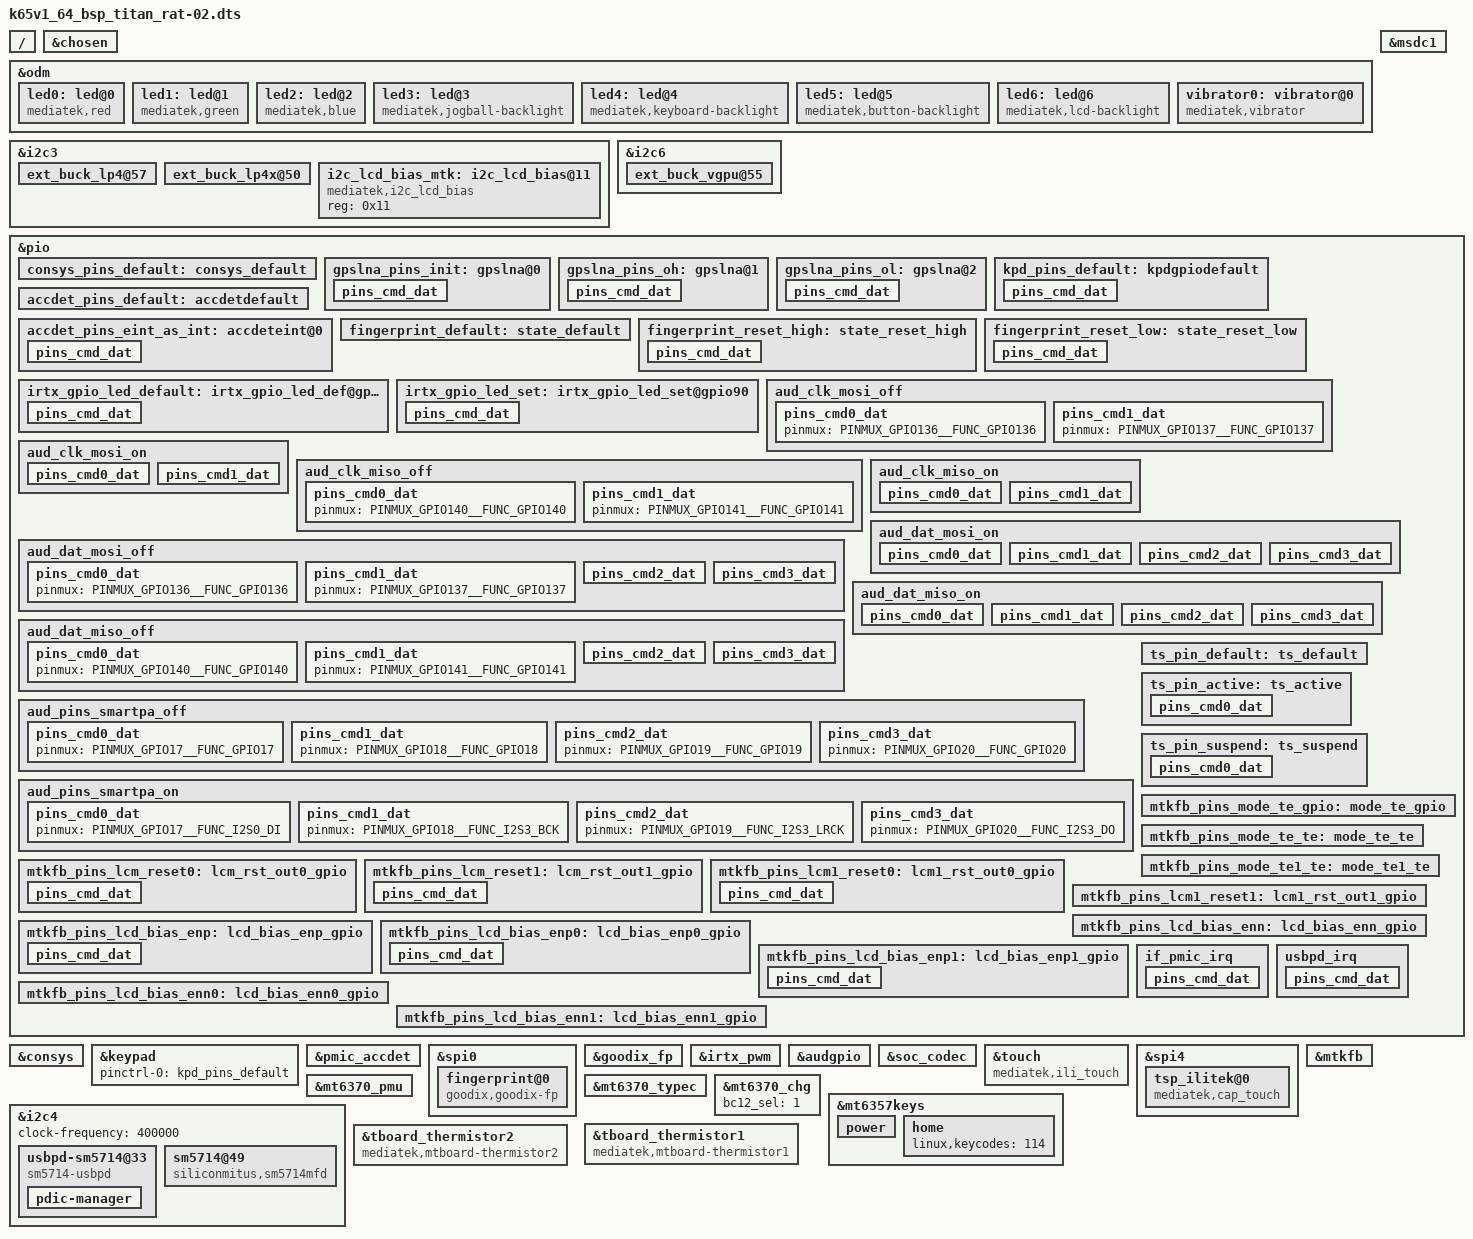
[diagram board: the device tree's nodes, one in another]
// SPDX-License-Identifier: GPL-2.0+
/*
 * Copyright (c) 2019 MediaTek Inc.
 *
 */

#include <dt-bindings/interrupt-controller/arm-gic.h>
#include <dt-bindings/interrupt-controller/irq.h>
#include <dt-bindings/pinctrl/mt6765-pinfunc.h>
#include <dt-bindings/clock/mt6765-clk.h>
#include <dt-bindings/mmc/mt6765-msdc.h>

/dts-v1/;
/plugin/;

/ {
	fragment@model {
	target-path = "/";
		__overlay__ {
			dtbo-hw_rev = <2>;
			dtbo-hw_rev_end = <255>;
		};
	};
};

/* chosen */
&chosen {

	/* fpga may has no lk, we need to specify display info here */
	/* fb buffer is reserved using this dts by memory node above */
	atag,videolfb-fb_base_h = <0x0>;
	atag,videolfb-fb_base_l = <0x5e605000>;
	atag,videolfb-islcmfound = <1>;
	/* because no lk, so lcm is not inited */
	atag,videolfb-islcm_inited = <0>;
	atag,videolfb-fps= <6000>;
	atag,videolfb-vramSize= <0x017bb000>;
	atag,videolfb-lcmname= "nt35695B_fhd_dsi_cmd_auo_rt5081_drv";
};

&odm {
	led0:led@0 {
		compatible = "mediatek,red";
		led_mode = <0>;
		data = <1>;
		pwm_config = <0 0 0 0 0>;
	};
	led1:led@1 {
		compatible = "mediatek,green";
		led_mode = <0>;
		data = <1>;
		pwm_config = <0 0 0 0 0>;
	};
	led2:led@2 {
		compatible = "mediatek,blue";
		led_mode = <0>;
		data = <1>;
		pwm_config = <0 0 0 0 0>;
	};
	led3:led@3 {
		compatible = "mediatek,jogball-backlight";
		led_mode = <0>;
		data = <1>;
		pwm_config = <0 0 0 0 0>;
	};
	led4:led@4 {
		compatible = "mediatek,keyboard-backlight";
		led_mode = <0>;
		data = <1>;
		pwm_config = <0 0 0 0 0>;
	};
	led5:led@5 {
		compatible = "mediatek,button-backlight";
		led_mode = <0>;
		data = <1>;
		pwm_config = <0 0 0 0 0>;
	};
	led6:led@6 {
		compatible = "mediatek,lcd-backlight";
		led_mode = <4>;
		data = <1>;
		pwm_config = <0 3 0 0 0>;
	};
	vibrator0:vibrator@0 {
		compatible = "mediatek,vibrator";
		vib_timer = <25>;
		vib_limit = <9>;
		vib_vol= <9>;
	};
};

/* MSDC1 */
&msdc1 {
	cd_level = /bits/ 8 <MSDC_CD_HIGH>;
	cd-gpios = <&pio 9 0>;
};
/* MSDC1 */

&i2c3 {
	ext_buck_lp4@57 {
		regulator-name ="ext_buck_vdd2";
		regulator-min-microvolt = <300000>;
		regulator-max-microvolt = <1300000>;
		vsel_pin = <0>;
	};

	ext_buck_lp4x@50 {
		regulator-name ="ext_buck_vddq";
		regulator-min-microvolt = <300000>;
		regulator-max-microvolt = <1300000>;
		vsel_pin = <1>;
	};
};

&i2c6 {
	ext_buck_vgpu@55 {
		regulator-name ="ext_buck_vgpu";
		regulator-min-microvolt = <300000>;
		regulator-max-microvolt = <1300000>;
		vsel_pin = <2>;
	};
};

/* CONSYS GPIO standardization */
&pio {
	consys_pins_default: consys_default {
	};
	gpslna_pins_init: gpslna@0 {
		pins_cmd_dat {
			pinmux = <PINMUX_GPIO150__FUNC_GPIO150>;
			output-low;
		};
	};
	gpslna_pins_oh: gpslna@1 {
		pins_cmd_dat {
			pinmux = <PINMUX_GPIO150__FUNC_GPIO150>;
			output-high;
		};
	};
	gpslna_pins_ol: gpslna@2 {
		pins_cmd_dat {
			pinmux = <PINMUX_GPIO150__FUNC_GPIO150>;
			slew-rate = <1>;
			output-low;
		};
	};
};
&consys {
	pinctrl-names = "default", "gps_lna_state_init",
		"gps_lna_state_oh", "gps_lna_state_ol";
	pinctrl-0 = <&consys_pins_default>;
	pinctrl-1 = <&gpslna_pins_init>;
	pinctrl-2 = <&gpslna_pins_oh>;
	pinctrl-3 = <&gpslna_pins_ol>;
	status = "okay";
};
/* CONSYS end */

&keypad {
	pinctrl-names = "default";
	pinctrl-0 = <&kpd_pins_default>;
};

&pio {
	kpd_pins_default: kpdgpiodefault {
		pins_cmd_dat {
			pinmux = <PINMUX_GPIO93__FUNC_KPCOL0>;
			bias-pull-up = <MTK_PUPD_SET_R1R0_10>;
			output-low;
			input-schmitt-enable;
		};
	};
};


/* accdet start */
&pmic_accdet {
	accdet-mic-vol = <6>;
	accdet-plugout-debounce = <1>;
	accdet-mic-mode = <1>;
	headset-mode-setting = <0x500 0x500 1 0x1f0
				0x800 0x800 0x20 0x44>;
	headset-eint-level-pol = <8>;
	headset-use-ap-eint = <0>;
	headset-eint-num = <0>;
	headset-eint-trig-mode = <0>;
	headset-key-mode = <1>;
	/*min_3pole--max_3pole--min_4pole--max_4pole--vol_bias*/
	headset-vol-threshold = <0 590 591 1680 2600>;
	headset-three-key-threshold = <0 80 220 400>;
	headset-three-key-threshold-CDD = <0 121 192 600>;
	headset-four-key-threshold = <0 58 121 192 400>;

	/* moisture SW mode config start, use external resister or not.
	 */
	moisture-ver = <1>;
	moisture_use_ext_res = <1>;
	/* moisture of water resister ohm, SW mode by auxadc*/
	moisture-water-r = <50000>;
	/* moisture SW mode config end */

	pinctrl-names = "default", "state_eint_as_int";
	pinctrl-0 = <&accdet_pins_default>;
	pinctrl-1 = <&accdet_pins_eint_as_int>;
	status = "okay";
};
&pio {
	accdet_pins_default: accdetdefault {
	};
	accdet_pins_eint_as_int: accdeteint@0 {
		pins_cmd_dat {
			pinmux = <PINMUX_GPIO9__FUNC_GPIO9>;
			slew-rate = <0>;
			bias-disable;
		};
	};
};
/* accdet end */

/* FINGERPRINT start */
&spi0 {
	#address-cells = <1>;
	#size-cells = <0>;
	fingerprint@0 {
		compatible = "goodix,goodix-fp";
		reg = <0>;
		spi-max-frequency = <8000000>;
		netlink-event = <30>;
		status = "okay";
	};
};

&goodix_fp {
	pinctrl-names = "default", "reset_high", "reset_low";
	pinctrl-0 = <&fingerprint_default>;
	pinctrl-1 = <&fingerprint_reset_high>;
	pinctrl-2 = <&fingerprint_reset_low>;
	status = "okay";
};

&pio {
	fingerprint_default: state_default {
	};
	fingerprint_reset_high: state_reset_high {
		pins_cmd_dat {
			pinmux = <PINMUX_GPIO172__FUNC_GPIO172>;
			slew-rate = <1>;
			output-high;
		};
	};
	fingerprint_reset_low: state_reset_low {
		pins_cmd_dat {
			pinmux = <PINMUX_GPIO172__FUNC_GPIO172>;
			slew-rate = <1>;
			output-low;
		};
	};
};
/* FINGERPRINT end */

/* IRTX GPIO end */
&irtx_pwm {
	pinctrl-names = "irtx_gpio_led_default", "irtx_gpio_led_set";
	pinctrl-0 = <&irtx_gpio_led_default>;
	pinctrl-1 = <&irtx_gpio_led_set>;
	status = "okay";
};
&pio {
	irtx_gpio_led_default:irtx_gpio_led_def@gpio90 {
		pins_cmd_dat {
			pinmux = <PINMUX_GPIO90__FUNC_GPIO90>;
			slew-rate = <1>;
			bias-disable;
			output-low;
			input-schmitt-enable = <0>;
		};
	};

	irtx_gpio_led_set:irtx_gpio_led_set@gpio90 {
		pins_cmd_dat {
			pinmux = <PINMUX_GPIO90__FUNC_PWM0>;
			slew-rate = <1>;
			output-high;
		};
	};
};
/* IRTX GPIO Settings -End */

/* AUDIO GPIO standardization */
&audgpio {
	pinctrl-names = "aud_clk_mosi_off",
			"aud_clk_mosi_on",
			"aud_clk_miso_off",
			"aud_clk_miso_on",
			"aud_dat_mosi_off",
			"aud_dat_mosi_on",
			"aud_dat_miso_off",
			"aud_dat_miso_on",
			"aud_smartpa_off",
			"aud_smartpa_on";
	pinctrl-0 = <&aud_clk_mosi_off>;
	pinctrl-1 = <&aud_clk_mosi_on>;
	pinctrl-2 = <&aud_clk_miso_off>;
	pinctrl-3 = <&aud_clk_miso_on>;
	pinctrl-4 = <&aud_dat_mosi_off>;
	pinctrl-5 = <&aud_dat_mosi_on>;
	pinctrl-6 = <&aud_dat_miso_off>;
	pinctrl-7 = <&aud_dat_miso_on>;
	pinctrl-8 = <&aud_pins_smartpa_off>;
	pinctrl-9 = <&aud_pins_smartpa_on>;
	status = "okay";
};

&pio {
	aud_clk_mosi_off: aud_clk_mosi_off {
		pins_cmd0_dat {
			pinmux = <PINMUX_GPIO136__FUNC_GPIO136>;
		};
		pins_cmd1_dat {
			pinmux = <PINMUX_GPIO137__FUNC_GPIO137>;
		};
	};

	aud_clk_mosi_on: aud_clk_mosi_on {
		pins_cmd0_dat {
			pinmux = <PINMUX_GPIO136__FUNC_AUD_CLK_MOSI>;
			input-schmitt-enable;
		};
		pins_cmd1_dat {
			pinmux = <PINMUX_GPIO137__FUNC_AUD_SYNC_MOSI>;
			input-schmitt-enable;
		};
	};

	aud_clk_miso_off: aud_clk_miso_off {
		pins_cmd0_dat {
			pinmux = <PINMUX_GPIO140__FUNC_GPIO140>;
		};
		pins_cmd1_dat {
			pinmux = <PINMUX_GPIO141__FUNC_GPIO141>;
		};
	};

	aud_clk_miso_on: aud_clk_miso_on {
		pins_cmd0_dat {
			pinmux = <PINMUX_GPIO140__FUNC_AUD_CLK_MISO>;
			input-schmitt-enable;
		};
		pins_cmd1_dat {
			pinmux = <PINMUX_GPIO141__FUNC_AUD_SYNC_MISO>;
			input-schmitt-enable;
		};
	};

	aud_dat_mosi_off: aud_dat_mosi_off {
		pins_cmd0_dat {
			pinmux = <PINMUX_GPIO136__FUNC_GPIO136>;
		};
		pins_cmd1_dat {
			pinmux = <PINMUX_GPIO137__FUNC_GPIO137>;
		};
		pins_cmd2_dat {
			pinmux = <PINMUX_GPIO138__FUNC_GPIO138>;
			input-enable;
			slew-rate = <0>;
			bias-disable;
		};
		pins_cmd3_dat {
			pinmux = <PINMUX_GPIO139__FUNC_GPIO139>;
			input-enable;
			slew-rate = <0>;
			bias-disable;
		};
	};

	aud_dat_mosi_on: aud_dat_mosi_on {
		pins_cmd0_dat {
			pinmux = <PINMUX_GPIO136__FUNC_AUD_CLK_MOSI>;
			input-schmitt-enable;
		};
		pins_cmd1_dat {
			pinmux = <PINMUX_GPIO137__FUNC_AUD_SYNC_MOSI>;
			input-schmitt-enable;
		};
		pins_cmd2_dat {
			pinmux = <PINMUX_GPIO138__FUNC_AUD_DAT_MOSI0>;
			input-schmitt-enable;
		};
		pins_cmd3_dat {
			pinmux = <PINMUX_GPIO139__FUNC_AUD_DAT_MOSI1>;
			input-schmitt-enable;
		};
	};

	aud_dat_miso_off: aud_dat_miso_off {
		pins_cmd0_dat {
			pinmux = <PINMUX_GPIO140__FUNC_GPIO140>;
		};
		pins_cmd1_dat {
			pinmux = <PINMUX_GPIO141__FUNC_GPIO141>;
		};
		pins_cmd2_dat {
			pinmux = <PINMUX_GPIO142__FUNC_GPIO142>;
			input-enable;
			slew-rate = <0>;
			bias-disable;
		};
		pins_cmd3_dat {
			pinmux = <PINMUX_GPIO143__FUNC_GPIO143>;
			input-enable;
			slew-rate = <0>;
			bias-disable;
		};
	};

	aud_dat_miso_on: aud_dat_miso_on {
		pins_cmd0_dat {
			pinmux = <PINMUX_GPIO140__FUNC_AUD_CLK_MISO>;
			input-schmitt-enable;
		};
		pins_cmd1_dat {
			pinmux = <PINMUX_GPIO141__FUNC_AUD_SYNC_MISO>;
			input-schmitt-enable;
		};
		pins_cmd2_dat {
			pinmux = <PINMUX_GPIO142__FUNC_AUD_DAT_MISO0>;
			input-schmitt-enable;
		};
		pins_cmd3_dat {
			pinmux = <PINMUX_GPIO143__FUNC_AUD_DAT_MISO1>;
			input-schmitt-enable;
		};
	};

	aud_pins_smartpa_off: aud_pins_smartpa_off {
		pins_cmd0_dat {
			pinmux = <PINMUX_GPIO17__FUNC_GPIO17>;
		};
		pins_cmd1_dat {
			pinmux = <PINMUX_GPIO18__FUNC_GPIO18>;
		};
		pins_cmd2_dat {
			pinmux = <PINMUX_GPIO19__FUNC_GPIO19>;
		};
		pins_cmd3_dat {
			pinmux = <PINMUX_GPIO20__FUNC_GPIO20>;
		};
	};

	aud_pins_smartpa_on: aud_pins_smartpa_on {
		pins_cmd0_dat {
			pinmux = <PINMUX_GPIO17__FUNC_I2S0_DI>;
		};
		pins_cmd1_dat {
			pinmux = <PINMUX_GPIO18__FUNC_I2S3_BCK>;
		};
		pins_cmd2_dat {
			pinmux = <PINMUX_GPIO19__FUNC_I2S3_LRCK>;
		};
		pins_cmd3_dat {
			pinmux = <PINMUX_GPIO20__FUNC_I2S3_DO>;
		};
	};
};
&soc_codec {
	always_pull_down_enable = <0>; /* select 1: enable, 0: disable */
	always_pull_low_off = <1>; /* select 1: enable, 0: disable */
};
/* AUDIO end */

/* TOUCH start */
&touch {
	compatible = "mediatek,ili_touch";
	/* IRQF_ONESHOT | IRQF_TRIGGER_LOW */
	touch,irq-gpio = <&pio 10 0x2008>;
	touch,reset-gpio = <&pio 172 0x2008>;
	interrupt-parent = <&pio>;
	interrupts = <10 0x2008>;
	/* vdd-supply = <&pm8994_lvs2>; */
	/* avdd-supply = <&pm8994_l22>; */
	pinctrl-names = "pmx_ts_active", "pmx_ts_suspend";
	pinctrl-0 = <&ts_pin_active>;
	pinctrl-1 = <&ts_pin_suspend>;
};

&spi4 {
	status = "okay";

	#address-cells = <1>;
	#size-cells = <0>;

	tsp_ilitek@0 {
		compatible = "mediatek,cap_touch";
		reg = <0>;
		spi-max-frequency = <5000000>;
	};

};

/* touch gpio start */
&pio {
	ts_pin_default: ts_default {
	};

	ts_pin_active: ts_active {
		pins_cmd0_dat {
			pinmux = <PINMUX_GPIO172__FUNC_GPIO172>;
			slew-rate = <1>;
			output-high;
		};
	};

	ts_pin_suspend: ts_suspend {
		pins_cmd0_dat {
			pinmux = <PINMUX_GPIO172__FUNC_GPIO172>;
			slew-rate = <1>;
			output-low;
		};
	};
};
/* touch gpio end */
/* TOUCH end */

/* DISPSYS GPIO standardization */
&pio {
	mtkfb_pins_mode_te_gpio: mode_te_gpio {
	};

	mtkfb_pins_mode_te_te: mode_te_te {
	};

	mtkfb_pins_mode_te1_te: mode_te1_te {
	};

	mtkfb_pins_lcm_reset0: lcm_rst_out0_gpio {
		pins_cmd_dat {
			pinmux = <PINMUX_GPIO45__FUNC_GPIO45>;
			slew-rate = <1>;
			output-low;
		};
	};

	mtkfb_pins_lcm_reset1: lcm_rst_out1_gpio {
		pins_cmd_dat {
			pinmux = <PINMUX_GPIO45__FUNC_GPIO45>;
			slew-rate = <1>;
			output-high;
		};
	};

	mtkfb_pins_lcm1_reset0: lcm1_rst_out0_gpio {
		pins_cmd_dat {
			pinmux = <PINMUX_GPIO45__FUNC_GPIO45>;
			slew-rate = <1>;
			output-low;
		};
	};

	mtkfb_pins_lcm1_reset1: lcm1_rst_out1_gpio {
	};

	mtkfb_pins_lcd_bias_enn: lcd_bias_enn_gpio {
	};

	mtkfb_pins_lcd_bias_enp: lcd_bias_enp_gpio {
		pins_cmd_dat {
			pinmux = <PINMUX_GPIO44__FUNC_GPIO44>;
			slew-rate = <1>;
			output-high;
		};
	};

	mtkfb_pins_lcd_bias_enp0: lcd_bias_enp0_gpio {
		pins_cmd_dat {
			pinmux = <PINMUX_GPIO44__FUNC_GPIO44>;
			slew-rate = <1>;
			output-low;
		};
	};

	mtkfb_pins_lcd_bias_enp1: lcd_bias_enp1_gpio {
		pins_cmd_dat {
			pinmux = <PINMUX_GPIO44__FUNC_GPIO44>;
			slew-rate = <1>;
			output-high;
		};
	};

	mtkfb_pins_lcd_bias_enn0: lcd_bias_enn0_gpio {
	};

	mtkfb_pins_lcd_bias_enn1: lcd_bias_enn1_gpio {
	};
};

&mtkfb {
	pinctrl-names = "mode_te_gpio",	"mode_te_te", "mode_te1_te", "lcm_rst_out0_gpio",
		"lcm_rst_out1_gpio", "lcm1_rst_out0_gpio", "lcm1_rst_out1_gpio",
		"lcd_bias_enn_gpio", "lcd_bias_enp_gpio","lcd_bias_enp0_gpio",
		"lcd_bias_enp1_gpio", "lcd_bias_enn0_gpio","lcd_bias_enn1_gpio";
	pinctrl-0 = <&mtkfb_pins_mode_te_gpio>;
	pinctrl-1 = <&mtkfb_pins_mode_te_te>;
	pinctrl-2 = <&mtkfb_pins_mode_te1_te>;
	pinctrl-3 = <&mtkfb_pins_lcm_reset0>;
	pinctrl-4 = <&mtkfb_pins_lcm_reset1>;
	pinctrl-5 = <&mtkfb_pins_lcm1_reset0>;
	pinctrl-6 = <&mtkfb_pins_lcm1_reset1>;
	pinctrl-7 = <&mtkfb_pins_lcd_bias_enn>;
	pinctrl-8 = <&mtkfb_pins_lcd_bias_enp>;
	pinctrl-9 = <&mtkfb_pins_lcd_bias_enp0>;
	pinctrl-10 = <&mtkfb_pins_lcd_bias_enp1>;
	pinctrl-11 = <&mtkfb_pins_lcd_bias_enn0>;
	pinctrl-12 = <&mtkfb_pins_lcd_bias_enn1>;
	status = "okay";
};
/* DISPSYS GPIO standardization end */

&mt6370_pmu {
	mt6370,intr_gpio_num = <0>; /* direct defined GPIO num */
	mt6370,intr_gpio = <&pio 0 0x0>;
};

&mt6370_typec {
	mt6370pd,intr_gpio_num = <53>; /* direct defined GPIO num */
	mt6370pd,intr_gpio = <&pio 53 0x0>;
};

&mt6370_chg {
	bc12_sel = <1>;
};

&pio {
	if_pmic_irq: if_pmic_irq {
		pins_cmd_dat {
			pinmux = <PINMUX_GPIO7__FUNC_GPIO7>;
			bias-disable;
			drive-strength = /bits/ 8 <1>;
		};
	};
	usbpd_irq: usbpd_irq {
		pins_cmd_dat {
			pinmux = <PINMUX_GPIO0__FUNC_GPIO0>;
			bias-disable;
			drive-strength = /bits/ 8 <4>;
		};
	};
};

&i2c4 {
	#address-cells = <1>;
	#size-cells = <0>;
	status = "okay";
	clock-frequency = <400000>;

	usbpd-sm5714@33 {
		status = "okay";
		compatible = "sm5714-usbpd";
		reg = <0x33>;
		pinctrl-names = "default";
		pinctrl-0 = <&usbpd_irq>;
		usbpd,usbpd_int = <&pio 0 0>;

		support_pd_role_swap;
		pdic-manager {
			/* sink */
			pdic,max_power = <5000>;
			pdic_op_power = <2500>;
			pdic_max_voltage = <6000>;
			pdic_max_current = <2000>;
			pdic,min_current = <500>;
			pdic,giveback = <0>;
			pdic,usb_com_capable = <1>;
			pdic,no_usb_suspend = <1>;

			/* source */
			source,max_voltage = <5000>;
			source,min_voltage = <4000>;
			source,max_power = <2500>;
		};
	};

	sm5714@49{
		status = "okay";
		compatible = "siliconmitus,sm5714mfd";
		reg = <0x49>;
		pinctrl-names = "default";
		pinctrl-0 = <&if_pmic_irq>;
		sm5714,irq-gpio = <&pio 7 0>;
		sm5714,wakeup;
	};
};

/* LCD BIAS */
&i2c3 {
	#address-cells = <1>;
	#size-cells = <0>;
	clock-frequency = <400000>;
	mediatek,use-open-drain;

	i2c_lcd_bias_mtk:i2c_lcd_bias@11 {
		compatible = "mediatek,i2c_lcd_bias";
		reg = <0x11>;
		status = "okay";
	};
};

&mt6357keys {
	power {
		linux,keycodes = <116>;
		wakeup-source;
	};
	home {
		linux,keycodes = <114>;
	};
};

&tboard_thermistor1{
		compatible = "mediatek,mtboard-thermistor1";
		io-channels = <&auxadc 4>;
		io-channel-names = "thermistor-ch0";
		interconnects = <&auxadc 4>;
};

&tboard_thermistor2{
		compatible = "mediatek,mtboard-thermistor2";
		io-channels = <&auxadc 0>;
		io-channel-names = "thermistor-ch1";
		interconnects = <&auxadc 0>;
};

#include "mediatek/k65v1_64_bsp_titan_rat/gpio02.dtsi"
#include "mediatek/k65v1_64_bsp_titan_rat/camera02.dtsi"
#include "samsung/battery_common.a12.dtsi"
#include "samsung/sm5714_fuelgauge.a12.dtsi"
/*End of this file, DO NOT ADD ANYTHING HERE*/
